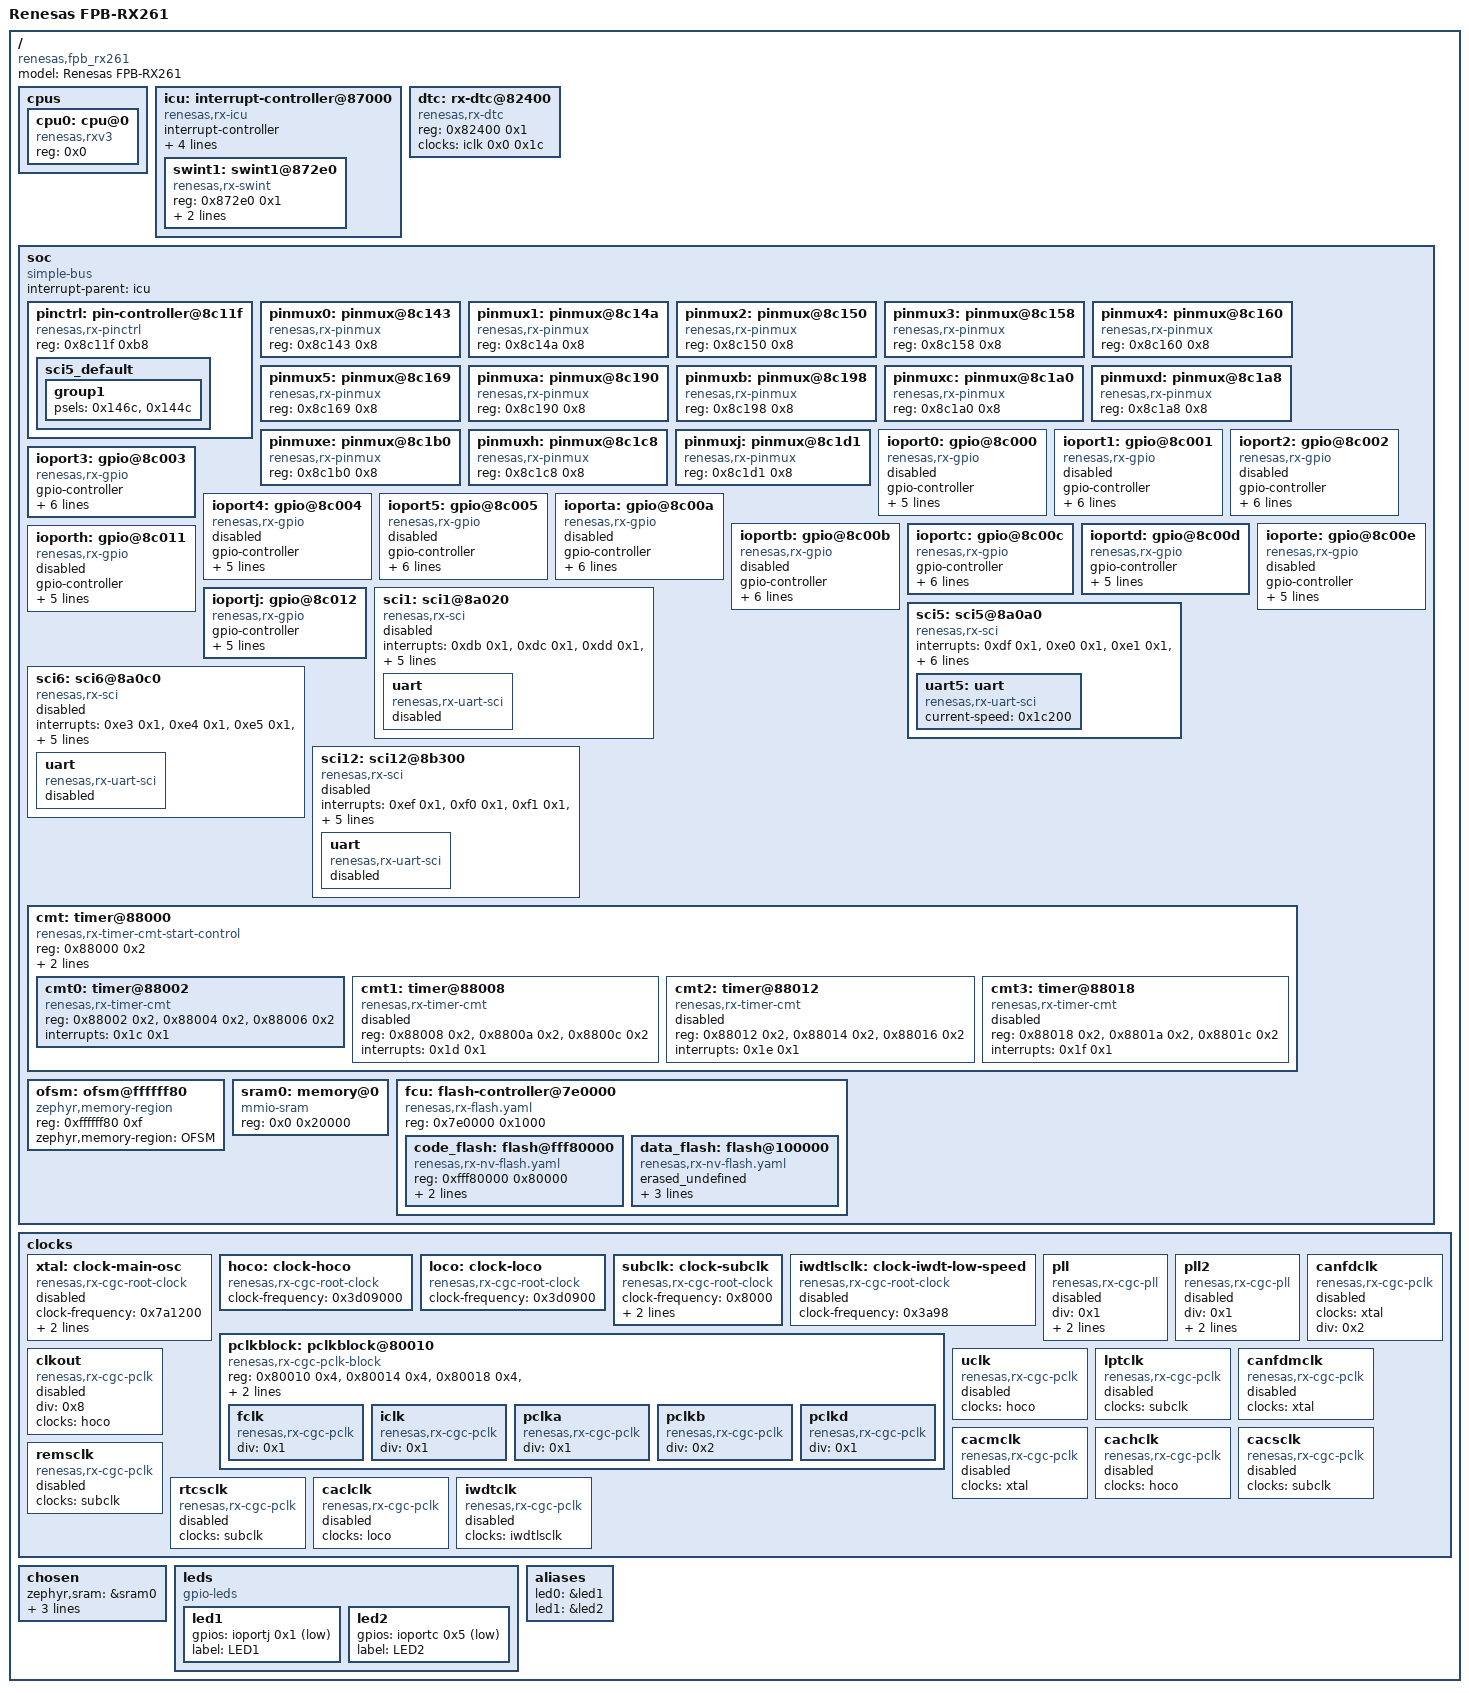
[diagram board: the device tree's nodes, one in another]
/dts-v1/;

/* node '/' defined in zephyr/dts/rx/renesas/rx261-common.dtsi:15 */
/ {
	#address-cells = < 0x1 >;         /* in zephyr/dts/rx/renesas/rx261-common.dtsi:16 */
	#size-cells = < 0x1 >;            /* in zephyr/dts/rx/renesas/rx261-common.dtsi:17 */
	model = "Renesas FPB-RX261";      /* in zephyr/boards/renesas/fpb_rx261/fpb_rx261.dts:14 */
	compatible = "renesas,fpb_rx261"; /* in zephyr/boards/renesas/fpb_rx261/fpb_rx261.dts:15 */

	/* node '/cpus' defined in zephyr/dts/rx/renesas/rx261-common.dtsi:19 */
	cpus {
		#address-cells = < 0x1 >; /* in zephyr/dts/rx/renesas/rx261-common.dtsi:20 */
		#size-cells = < 0x0 >;    /* in zephyr/dts/rx/renesas/rx261-common.dtsi:21 */

		/* node '/cpus/cpu@0' defined in zephyr/dts/rx/renesas/rx261-common.dtsi:23 */
		cpu0: cpu@0 {
			compatible = "renesas,rxv3"; /* in zephyr/dts/rx/renesas/rx261-common.dtsi:24 */
			device_type = "cpu";         /* in zephyr/dts/rx/renesas/rx261-common.dtsi:25 */
			reg = < 0x0 >;               /* in zephyr/dts/rx/renesas/rx261-common.dtsi:26 */
			status = "okay";             /* in zephyr/dts/rx/renesas/rx261-common.dtsi:27 */
		};
	};

	/* node '/interrupt-controller@87000' defined in zephyr/dts/rx/renesas/rx261-common.dtsi:31 */
	icu: interrupt-controller@87000 {
		#interrupt-cells = < 0x2 >;    /* in zephyr/dts/rx/renesas/rx261-common.dtsi:32 */
		#address-cells = < 0x1 >;      /* in zephyr/dts/rx/renesas/rx261-common.dtsi:33 */
		#size-cells = < 0x1 >;         /* in zephyr/dts/rx/renesas/rx261-common.dtsi:34 */
		compatible = "renesas,rx-icu"; /* in zephyr/dts/rx/renesas/rx261-common.dtsi:35 */
		interrupt-controller;          /* in zephyr/dts/rx/renesas/rx261-common.dtsi:36 */
		reg = < 0x87000 0xff >,
		      < 0x87200 0x1f >,
		      < 0x87300 0xff >,
		      < 0x872f0 0x2 >,
		      < 0x87500 0xf >,
		      < 0x87510 0x1 >,
		      < 0x87514 0x1 >,
		      < 0x87580 0x1 >,
		      < 0x87581 0x1 >,
		      < 0x87582 0x1 >;         /* in zephyr/dts/rx/renesas/rx261-common.dtsi:37 */
		reg-names = "IR",
		            "IER",
		            "IPR",
		            "FIR",
		            "IRQCR",
		            "IRQFLTE",
		            "IRQFLTC0",
		            "NMISR",
		            "NMIER",
		            "NMICLR";          /* in zephyr/dts/rx/renesas/rx261-common.dtsi:47 */
		phandle = < 0x1 >;             /* in zephyr/dts/rx/renesas/rx261-common.dtsi:54 */

		/* node '/interrupt-controller@87000/swint1@872e0' defined in zephyr/dts/rx/renesas/rx261-common.dtsi:50 */
		swint1: swint1@872e0 {
			compatible = "renesas,rx-swint"; /* in zephyr/dts/rx/renesas/rx261-common.dtsi:51 */
			reg = < 0x872e0 0x1 >;           /* in zephyr/dts/rx/renesas/rx261-common.dtsi:52 */
			interrupts = < 0x1b 0xe >;       /* in zephyr/dts/rx/renesas/rx261-common.dtsi:53 */
			interrupt-parent = < &icu >;     /* in zephyr/dts/rx/renesas/rx261-common.dtsi:54 */
			status = "okay";                 /* in zephyr/dts/rx/renesas/rx261-common.dtsi:55 */
		};
	};

	/* node '/rx-dtc@82400' defined in zephyr/dts/rx/renesas/rx261-common.dtsi:59 */
	dtc: rx-dtc@82400 {
		compatible = "renesas,rx-dtc"; /* in zephyr/dts/rx/renesas/rx261-common.dtsi:60 */
		reg = < 0x82400 0x1 >;         /* in zephyr/dts/rx/renesas/rx261-common.dtsi:61 */
		clocks = < &iclk 0x0 0x1c >;   /* in zephyr/dts/rx/renesas/rx261-common.dtsi:62 */
		status = "okay";               /* in zephyr/dts/rx/renesas/rx261-common.dtsi:63 */
		phandle = < 0x11 >;            /* in zephyr/dts/rx/renesas/rx261-common.dtsi:400 */
	};

	/* node '/soc' defined in zephyr/dts/rx/renesas/rx261-common.dtsi:66 */
	soc {
		#address-cells = < 0x1 >;    /* in zephyr/dts/rx/renesas/rx261-common.dtsi:67 */
		#size-cells = < 0x1 >;       /* in zephyr/dts/rx/renesas/rx261-common.dtsi:68 */
		device_type = "soc";         /* in zephyr/dts/rx/renesas/rx261-common.dtsi:69 */
		compatible = "simple-bus";   /* in zephyr/dts/rx/renesas/rx261-common.dtsi:70 */
		interrupt-parent = < &icu >; /* in zephyr/dts/rx/renesas/rx261-common.dtsi:71 */

		/* node '/soc/pin-controller@8c11f' defined in zephyr/dts/rx/renesas/rx261-common.dtsi:73 */
		pinctrl: pin-controller@8c11f {
			compatible = "renesas,rx-pinctrl"; /* in zephyr/dts/rx/renesas/rx261-common.dtsi:74 */
			reg = < 0x8c11f 0xb8 >;            /* in zephyr/dts/rx/renesas/rx261-common.dtsi:75 */
			status = "okay";                   /* in zephyr/dts/rx/renesas/rx261-common.dtsi:76 */

			/* node '/soc/pin-controller@8c11f/sci5_default' defined in zephyr/boards/renesas/fpb_rx261/fpb_rx261-pinctrl.dtsi:8 */
			sci5_default: sci5_default {
				phandle = < 0x12 >; /* in zephyr/boards/renesas/fpb_rx261/fpb_rx261.dts:78 */

				/* node '/soc/pin-controller@8c11f/sci5_default/group1' defined in zephyr/boards/renesas/fpb_rx261/fpb_rx261-pinctrl.dtsi:9 */
				group1 {
					psels = < 0x146c >,
					        < 0x144c >; /* in zephyr/boards/renesas/fpb_rx261/fpb_rx261-pinctrl.dtsi:10 */
				};
			};
		};

		/* node '/soc/pinmux@8c143' defined in zephyr/dts/rx/renesas/rx261-common.dtsi:79 */
		pinmux0: pinmux@8c143 {
			compatible = "renesas,rx-pinmux"; /* in zephyr/dts/rx/renesas/rx261-common.dtsi:80 */
			#pinmux-cells = < 0x2 >;          /* in zephyr/dts/rx/renesas/rx261-common.dtsi:81 */
			reg = < 0x8c143 0x8 >;            /* in zephyr/dts/rx/renesas/rx261-common.dtsi:82 */
			status = "okay";                  /* in zephyr/dts/rx/renesas/rx261-common.dtsi:83 */
			phandle = < 0x3 >;                /* in zephyr/dts/rx/renesas/rx261-common.dtsi:182 */
		};

		/* node '/soc/pinmux@8c14a' defined in zephyr/dts/rx/renesas/rx261-common.dtsi:86 */
		pinmux1: pinmux@8c14a {
			compatible = "renesas,rx-pinmux"; /* in zephyr/dts/rx/renesas/rx261-common.dtsi:87 */
			#pinmux-cells = < 0x2 >;          /* in zephyr/dts/rx/renesas/rx261-common.dtsi:88 */
			reg = < 0x8c14a 0x8 >;            /* in zephyr/dts/rx/renesas/rx261-common.dtsi:89 */
			status = "okay";                  /* in zephyr/dts/rx/renesas/rx261-common.dtsi:90 */
			phandle = < 0x4 >;                /* in zephyr/dts/rx/renesas/rx261-common.dtsi:200 */
		};

		/* node '/soc/pinmux@8c150' defined in zephyr/dts/rx/renesas/rx261-common.dtsi:93 */
		pinmux2: pinmux@8c150 {
			compatible = "renesas,rx-pinmux"; /* in zephyr/dts/rx/renesas/rx261-common.dtsi:94 */
			#pinmux-cells = < 0x2 >;          /* in zephyr/dts/rx/renesas/rx261-common.dtsi:95 */
			reg = < 0x8c150 0x8 >;            /* in zephyr/dts/rx/renesas/rx261-common.dtsi:96 */
			status = "okay";                  /* in zephyr/dts/rx/renesas/rx261-common.dtsi:97 */
			phandle = < 0x5 >;                /* in zephyr/dts/rx/renesas/rx261-common.dtsi:218 */
		};

		/* node '/soc/pinmux@8c158' defined in zephyr/dts/rx/renesas/rx261-common.dtsi:100 */
		pinmux3: pinmux@8c158 {
			compatible = "renesas,rx-pinmux"; /* in zephyr/dts/rx/renesas/rx261-common.dtsi:101 */
			#pinmux-cells = < 0x2 >;          /* in zephyr/dts/rx/renesas/rx261-common.dtsi:102 */
			reg = < 0x8c158 0x8 >;            /* in zephyr/dts/rx/renesas/rx261-common.dtsi:103 */
			status = "okay";                  /* in zephyr/dts/rx/renesas/rx261-common.dtsi:104 */
			phandle = < 0x6 >;                /* in zephyr/dts/rx/renesas/rx261-common.dtsi:236 */
		};

		/* node '/soc/pinmux@8c160' defined in zephyr/dts/rx/renesas/rx261-common.dtsi:107 */
		pinmux4: pinmux@8c160 {
			compatible = "renesas,rx-pinmux"; /* in zephyr/dts/rx/renesas/rx261-common.dtsi:108 */
			#pinmux-cells = < 0x2 >;          /* in zephyr/dts/rx/renesas/rx261-common.dtsi:109 */
			reg = < 0x8c160 0x8 >;            /* in zephyr/dts/rx/renesas/rx261-common.dtsi:110 */
			status = "okay";                  /* in zephyr/dts/rx/renesas/rx261-common.dtsi:111 */
			phandle = < 0x7 >;                /* in zephyr/dts/rx/renesas/rx261-common.dtsi:252 */
		};

		/* node '/soc/pinmux@8c169' defined in zephyr/dts/rx/renesas/rx261-common.dtsi:114 */
		pinmux5: pinmux@8c169 {
			compatible = "renesas,rx-pinmux"; /* in zephyr/dts/rx/renesas/rx261-common.dtsi:115 */
			#pinmux-cells = < 0x2 >;          /* in zephyr/dts/rx/renesas/rx261-common.dtsi:116 */
			reg = < 0x8c169 0x8 >;            /* in zephyr/dts/rx/renesas/rx261-common.dtsi:117 */
			status = "okay";                  /* in zephyr/dts/rx/renesas/rx261-common.dtsi:118 */
			phandle = < 0x8 >;                /* in zephyr/dts/rx/renesas/rx261-common.dtsi:270 */
		};

		/* node '/soc/pinmux@8c190' defined in zephyr/dts/rx/renesas/rx261-common.dtsi:121 */
		pinmuxa: pinmux@8c190 {
			compatible = "renesas,rx-pinmux"; /* in zephyr/dts/rx/renesas/rx261-common.dtsi:122 */
			#pinmux-cells = < 0x2 >;          /* in zephyr/dts/rx/renesas/rx261-common.dtsi:123 */
			reg = < 0x8c190 0x8 >;            /* in zephyr/dts/rx/renesas/rx261-common.dtsi:124 */
			status = "okay";                  /* in zephyr/dts/rx/renesas/rx261-common.dtsi:125 */
			phandle = < 0x9 >;                /* in zephyr/dts/rx/renesas/rx261-common.dtsi:288 */
		};

		/* node '/soc/pinmux@8c198' defined in zephyr/dts/rx/renesas/rx261-common.dtsi:128 */
		pinmuxb: pinmux@8c198 {
			compatible = "renesas,rx-pinmux"; /* in zephyr/dts/rx/renesas/rx261-common.dtsi:129 */
			#pinmux-cells = < 0x2 >;          /* in zephyr/dts/rx/renesas/rx261-common.dtsi:130 */
			reg = < 0x8c198 0x8 >;            /* in zephyr/dts/rx/renesas/rx261-common.dtsi:131 */
			status = "okay";                  /* in zephyr/dts/rx/renesas/rx261-common.dtsi:132 */
			phandle = < 0xa >;                /* in zephyr/dts/rx/renesas/rx261-common.dtsi:306 */
		};

		/* node '/soc/pinmux@8c1a0' defined in zephyr/dts/rx/renesas/rx261-common.dtsi:135 */
		pinmuxc: pinmux@8c1a0 {
			compatible = "renesas,rx-pinmux"; /* in zephyr/dts/rx/renesas/rx261-common.dtsi:136 */
			#pinmux-cells = < 0x2 >;          /* in zephyr/dts/rx/renesas/rx261-common.dtsi:137 */
			reg = < 0x8c1a0 0x8 >;            /* in zephyr/dts/rx/renesas/rx261-common.dtsi:138 */
			status = "okay";                  /* in zephyr/dts/rx/renesas/rx261-common.dtsi:139 */
			phandle = < 0xb >;                /* in zephyr/dts/rx/renesas/rx261-common.dtsi:324 */
		};

		/* node '/soc/pinmux@8c1a8' defined in zephyr/dts/rx/renesas/rx261-common.dtsi:142 */
		pinmuxd: pinmux@8c1a8 {
			compatible = "renesas,rx-pinmux"; /* in zephyr/dts/rx/renesas/rx261-common.dtsi:143 */
			#pinmux-cells = < 0x2 >;          /* in zephyr/dts/rx/renesas/rx261-common.dtsi:144 */
			reg = < 0x8c1a8 0x8 >;            /* in zephyr/dts/rx/renesas/rx261-common.dtsi:145 */
			status = "okay";                  /* in zephyr/dts/rx/renesas/rx261-common.dtsi:146 */
			phandle = < 0xc >;                /* in zephyr/dts/rx/renesas/rx261-common.dtsi:341 */
		};

		/* node '/soc/pinmux@8c1b0' defined in zephyr/dts/rx/renesas/rx261-common.dtsi:149 */
		pinmuxe: pinmux@8c1b0 {
			compatible = "renesas,rx-pinmux"; /* in zephyr/dts/rx/renesas/rx261-common.dtsi:150 */
			#pinmux-cells = < 0x2 >;          /* in zephyr/dts/rx/renesas/rx261-common.dtsi:151 */
			reg = < 0x8c1b0 0x8 >;            /* in zephyr/dts/rx/renesas/rx261-common.dtsi:152 */
			status = "okay";                  /* in zephyr/dts/rx/renesas/rx261-common.dtsi:153 */
			phandle = < 0xd >;                /* in zephyr/dts/rx/renesas/rx261-common.dtsi:358 */
		};

		/* node '/soc/pinmux@8c1c8' defined in zephyr/dts/rx/renesas/rx261-common.dtsi:156 */
		pinmuxh: pinmux@8c1c8 {
			compatible = "renesas,rx-pinmux"; /* in zephyr/dts/rx/renesas/rx261-common.dtsi:157 */
			#pinmux-cells = < 0x2 >;          /* in zephyr/dts/rx/renesas/rx261-common.dtsi:158 */
			reg = < 0x8c1c8 0x8 >;            /* in zephyr/dts/rx/renesas/rx261-common.dtsi:159 */
			status = "okay";                  /* in zephyr/dts/rx/renesas/rx261-common.dtsi:160 */
			phandle = < 0xe >;                /* in zephyr/dts/rx/renesas/rx261-common.dtsi:374 */
		};

		/* node '/soc/pinmux@8c1d1' defined in zephyr/dts/rx/renesas/rx261-common.dtsi:163 */
		pinmuxj: pinmux@8c1d1 {
			compatible = "renesas,rx-pinmux"; /* in zephyr/dts/rx/renesas/rx261-common.dtsi:164 */
			#pinmux-cells = < 0x2 >;          /* in zephyr/dts/rx/renesas/rx261-common.dtsi:165 */
			reg = < 0x8c1d1 0x8 >;            /* in zephyr/dts/rx/renesas/rx261-common.dtsi:166 */
			status = "okay";                  /* in zephyr/dts/rx/renesas/rx261-common.dtsi:167 */
			phandle = < 0xf >;                /* in zephyr/dts/rx/renesas/rx261-common.dtsi:390 */
		};

		/* node '/soc/gpio@8c000' defined in zephyr/dts/rx/renesas/rx261-common.dtsi:170 */
		ioport0: gpio@8c000 {
			compatible = "renesas,rx-gpio"; /* in zephyr/dts/rx/renesas/rx261-common.dtsi:171 */
			gpio-controller;                /* in zephyr/dts/rx/renesas/rx261-common.dtsi:172 */
			#gpio-cells = < 0x2 >;          /* in zephyr/dts/rx/renesas/rx261-common.dtsi:173 */
			ngpios = < 0x5 >;               /* in zephyr/dts/rx/renesas/rx261-common.dtsi:174 */
			port = < 0x0 >;                 /* in zephyr/dts/rx/renesas/rx261-common.dtsi:175 */
			reg = < 0x8c000 0x1 >,
			      < 0x8c020 0x1 >,
			      < 0x8c040 0x1 >,
			      < 0x8c060 0x1 >,
			      < 0x8c0c0 0x1 >;          /* in zephyr/dts/rx/renesas/rx261-common.dtsi:176 */
			reg-names = "PDR",
			            "PODR",
			            "PIDR",
			            "PMR",
			            "PCR";              /* in zephyr/dts/rx/renesas/rx261-common.dtsi:181 */
			pinmux = < &pinmux0 >;          /* in zephyr/dts/rx/renesas/rx261-common.dtsi:182 */
			status = "disabled";            /* in zephyr/dts/rx/renesas/rx261-common.dtsi:183 */
		};

		/* node '/soc/gpio@8c001' defined in zephyr/dts/rx/renesas/rx261-common.dtsi:186 */
		ioport1: gpio@8c001 {
			compatible = "renesas,rx-gpio"; /* in zephyr/dts/rx/renesas/rx261-common.dtsi:187 */
			gpio-controller;                /* in zephyr/dts/rx/renesas/rx261-common.dtsi:188 */
			#gpio-cells = < 0x2 >;          /* in zephyr/dts/rx/renesas/rx261-common.dtsi:189 */
			ngpios = < 0x8 >;               /* in zephyr/dts/rx/renesas/rx261-common.dtsi:190 */
			port = < 0x1 >;                 /* in zephyr/dts/rx/renesas/rx261-common.dtsi:191 */
			reg = < 0x8c001 0x1 >,
			      < 0x8c021 0x1 >,
			      < 0x8c041 0x1 >,
			      < 0x8c061 0x1 >,
			      < 0x8c082 0x1 >,
			      < 0x8c083 0x1 >,
			      < 0x8c0c1 0x1 >;          /* in zephyr/dts/rx/renesas/rx261-common.dtsi:192 */
			reg-names = "PDR",
			            "PODR",
			            "PIDR",
			            "PMR",
			            "ODR0",
			            "ODR1",
			            "PCR";              /* in zephyr/dts/rx/renesas/rx261-common.dtsi:199 */
			pinmux = < &pinmux1 >;          /* in zephyr/dts/rx/renesas/rx261-common.dtsi:200 */
			status = "disabled";            /* in zephyr/dts/rx/renesas/rx261-common.dtsi:201 */
		};

		/* node '/soc/gpio@8c002' defined in zephyr/dts/rx/renesas/rx261-common.dtsi:204 */
		ioport2: gpio@8c002 {
			compatible = "renesas,rx-gpio"; /* in zephyr/dts/rx/renesas/rx261-common.dtsi:205 */
			gpio-controller;                /* in zephyr/dts/rx/renesas/rx261-common.dtsi:206 */
			#gpio-cells = < 0x2 >;          /* in zephyr/dts/rx/renesas/rx261-common.dtsi:207 */
			ngpios = < 0x8 >;               /* in zephyr/dts/rx/renesas/rx261-common.dtsi:208 */
			port = < 0x2 >;                 /* in zephyr/dts/rx/renesas/rx261-common.dtsi:209 */
			reg = < 0x8c002 0x1 >,
			      < 0x8c022 0x1 >,
			      < 0x8c042 0x1 >,
			      < 0x8c062 0x1 >,
			      < 0x8c084 0x1 >,
			      < 0x8c085 0x1 >,
			      < 0x8c0c2 0x1 >;          /* in zephyr/dts/rx/renesas/rx261-common.dtsi:210 */
			reg-names = "PDR",
			            "PODR",
			            "PIDR",
			            "PMR",
			            "ODR0",
			            "ODR1",
			            "PCR";              /* in zephyr/dts/rx/renesas/rx261-common.dtsi:217 */
			pinmux = < &pinmux2 >;          /* in zephyr/dts/rx/renesas/rx261-common.dtsi:218 */
			status = "disabled";            /* in zephyr/dts/rx/renesas/rx261-common.dtsi:219 */
		};

		/* node '/soc/gpio@8c003' defined in zephyr/dts/rx/renesas/rx261-common.dtsi:222 */
		ioport3: gpio@8c003 {
			compatible = "renesas,rx-gpio"; /* in zephyr/dts/rx/renesas/rx261-common.dtsi:223 */
			gpio-controller;                /* in zephyr/dts/rx/renesas/rx261-common.dtsi:224 */
			#gpio-cells = < 0x2 >;          /* in zephyr/dts/rx/renesas/rx261-common.dtsi:225 */
			ngpios = < 0x8 >;               /* in zephyr/dts/rx/renesas/rx261-common.dtsi:226 */
			port = < 0x3 >;                 /* in zephyr/dts/rx/renesas/rx261-common.dtsi:227 */
			reg = < 0x8c003 0x1 >,
			      < 0x8c023 0x1 >,
			      < 0x8c043 0x1 >,
			      < 0x8c063 0x1 >,
			      < 0x8c086 0x1 >,
			      < 0x8c087 0x1 >,
			      < 0x8c0c3 0x1 >;          /* in zephyr/dts/rx/renesas/rx261-common.dtsi:228 */
			reg-names = "PDR",
			            "PODR",
			            "PIDR",
			            "PMR",
			            "ODR0",
			            "ODR1",
			            "PCR";              /* in zephyr/dts/rx/renesas/rx261-common.dtsi:235 */
			pinmux = < &pinmux3 >;          /* in zephyr/dts/rx/renesas/rx261-common.dtsi:236 */
			status = "okay";                /* in zephyr/boards/renesas/fpb_rx261/fpb_rx261.dts:66 */
		};

		/* node '/soc/gpio@8c004' defined in zephyr/dts/rx/renesas/rx261-common.dtsi:240 */
		ioport4: gpio@8c004 {
			compatible = "renesas,rx-gpio"; /* in zephyr/dts/rx/renesas/rx261-common.dtsi:241 */
			gpio-controller;                /* in zephyr/dts/rx/renesas/rx261-common.dtsi:242 */
			#gpio-cells = < 0x2 >;          /* in zephyr/dts/rx/renesas/rx261-common.dtsi:243 */
			ngpios = < 0x8 >;               /* in zephyr/dts/rx/renesas/rx261-common.dtsi:244 */
			port = < 0x4 >;                 /* in zephyr/dts/rx/renesas/rx261-common.dtsi:245 */
			reg = < 0x8c004 0x1 >,
			      < 0x8c024 0x1 >,
			      < 0x8c044 0x1 >,
			      < 0x8c064 0x1 >,
			      < 0x8c0c4 0x1 >;          /* in zephyr/dts/rx/renesas/rx261-common.dtsi:246 */
			reg-names = "PDR",
			            "PODR",
			            "PIDR",
			            "PMR",
			            "PCR";              /* in zephyr/dts/rx/renesas/rx261-common.dtsi:251 */
			pinmux = < &pinmux4 >;          /* in zephyr/dts/rx/renesas/rx261-common.dtsi:252 */
			status = "disabled";            /* in zephyr/dts/rx/renesas/rx261-common.dtsi:253 */
		};

		/* node '/soc/gpio@8c005' defined in zephyr/dts/rx/renesas/rx261-common.dtsi:256 */
		ioport5: gpio@8c005 {
			compatible = "renesas,rx-gpio"; /* in zephyr/dts/rx/renesas/rx261-common.dtsi:257 */
			gpio-controller;                /* in zephyr/dts/rx/renesas/rx261-common.dtsi:258 */
			#gpio-cells = < 0x2 >;          /* in zephyr/dts/rx/renesas/rx261-common.dtsi:259 */
			ngpios = < 0x8 >;               /* in zephyr/dts/rx/renesas/rx261-common.dtsi:260 */
			port = < 0x5 >;                 /* in zephyr/dts/rx/renesas/rx261-common.dtsi:261 */
			reg = < 0x8c005 0x1 >,
			      < 0x8c025 0x1 >,
			      < 0x8c045 0x1 >,
			      < 0x8c065 0x1 >,
			      < 0x8c08a 0x1 >,
			      < 0x8c08b 0x1 >,
			      < 0x8c0c5 0x1 >;          /* in zephyr/dts/rx/renesas/rx261-common.dtsi:262 */
			reg-names = "PDR",
			            "PODR",
			            "PIDR",
			            "PMR",
			            "ODR0",
			            "ODR1",
			            "PCR";              /* in zephyr/dts/rx/renesas/rx261-common.dtsi:269 */
			pinmux = < &pinmux5 >;          /* in zephyr/dts/rx/renesas/rx261-common.dtsi:270 */
			status = "disabled";            /* in zephyr/dts/rx/renesas/rx261-common.dtsi:271 */
		};

		/* node '/soc/gpio@8c00a' defined in zephyr/dts/rx/renesas/rx261-common.dtsi:274 */
		ioporta: gpio@8c00a {
			compatible = "renesas,rx-gpio"; /* in zephyr/dts/rx/renesas/rx261-common.dtsi:275 */
			gpio-controller;                /* in zephyr/dts/rx/renesas/rx261-common.dtsi:276 */
			#gpio-cells = < 0x2 >;          /* in zephyr/dts/rx/renesas/rx261-common.dtsi:277 */
			ngpios = < 0x8 >;               /* in zephyr/dts/rx/renesas/rx261-common.dtsi:278 */
			port = < 0xa >;                 /* in zephyr/dts/rx/renesas/rx261-common.dtsi:279 */
			reg = < 0x8c00a 0x1 >,
			      < 0x8c02a 0x1 >,
			      < 0x8c04a 0x1 >,
			      < 0x8c06a 0x1 >,
			      < 0x8c094 0x1 >,
			      < 0x8c095 0x1 >,
			      < 0x8c0ca 0x1 >;          /* in zephyr/dts/rx/renesas/rx261-common.dtsi:280 */
			reg-names = "PDR",
			            "PODR",
			            "PIDR",
			            "PMR",
			            "ODR0",
			            "ODR1",
			            "PCR";              /* in zephyr/dts/rx/renesas/rx261-common.dtsi:287 */
			pinmux = < &pinmuxa >;          /* in zephyr/dts/rx/renesas/rx261-common.dtsi:288 */
			status = "disabled";            /* in zephyr/dts/rx/renesas/rx261-common.dtsi:289 */
		};

		/* node '/soc/gpio@8c00b' defined in zephyr/dts/rx/renesas/rx261-common.dtsi:292 */
		ioportb: gpio@8c00b {
			compatible = "renesas,rx-gpio"; /* in zephyr/dts/rx/renesas/rx261-common.dtsi:293 */
			gpio-controller;                /* in zephyr/dts/rx/renesas/rx261-common.dtsi:294 */
			#gpio-cells = < 0x2 >;          /* in zephyr/dts/rx/renesas/rx261-common.dtsi:295 */
			ngpios = < 0x8 >;               /* in zephyr/dts/rx/renesas/rx261-common.dtsi:296 */
			port = < 0xb >;                 /* in zephyr/dts/rx/renesas/rx261-common.dtsi:297 */
			reg = < 0x8c00b 0x1 >,
			      < 0x8c02b 0x1 >,
			      < 0x8c04b 0x1 >,
			      < 0x8c06b 0x1 >,
			      < 0x8c096 0x1 >,
			      < 0x8c097 0x1 >,
			      < 0x8c0cb 0x1 >;          /* in zephyr/dts/rx/renesas/rx261-common.dtsi:298 */
			reg-names = "PDR",
			            "PODR",
			            "PIDR",
			            "PMR",
			            "ODR0",
			            "ODR1",
			            "PCR";              /* in zephyr/dts/rx/renesas/rx261-common.dtsi:305 */
			pinmux = < &pinmuxb >;          /* in zephyr/dts/rx/renesas/rx261-common.dtsi:306 */
			status = "disabled";            /* in zephyr/dts/rx/renesas/rx261-common.dtsi:307 */
		};

		/* node '/soc/gpio@8c00c' defined in zephyr/dts/rx/renesas/rx261-common.dtsi:310 */
		ioportc: gpio@8c00c {
			compatible = "renesas,rx-gpio"; /* in zephyr/dts/rx/renesas/rx261-common.dtsi:311 */
			gpio-controller;                /* in zephyr/dts/rx/renesas/rx261-common.dtsi:312 */
			#gpio-cells = < 0x2 >;          /* in zephyr/dts/rx/renesas/rx261-common.dtsi:313 */
			ngpios = < 0x8 >;               /* in zephyr/dts/rx/renesas/rx261-common.dtsi:314 */
			port = < 0xc >;                 /* in zephyr/dts/rx/renesas/rx261-common.dtsi:315 */
			reg = < 0x8c00c 0x1 >,
			      < 0x8c02c 0x1 >,
			      < 0x8c04c 0x1 >,
			      < 0x8c06c 0x1 >,
			      < 0x8c098 0x1 >,
			      < 0x8c099 0x1 >,
			      < 0x8c0cc 0x1 >;          /* in zephyr/dts/rx/renesas/rx261-common.dtsi:316 */
			reg-names = "PDR",
			            "PODR",
			            "PIDR",
			            "PMR",
			            "ODR0",
			            "ODR1",
			            "PCR";              /* in zephyr/dts/rx/renesas/rx261-common.dtsi:323 */
			pinmux = < &pinmuxc >;          /* in zephyr/dts/rx/renesas/rx261-common.dtsi:324 */
			status = "okay";                /* in zephyr/boards/renesas/fpb_rx261/fpb_rx261.dts:70 */
			phandle = < 0x19 >;             /* in zephyr/boards/renesas/fpb_rx261/fpb_rx261.dts:33 */
		};

		/* node '/soc/gpio@8c00d' defined in zephyr/dts/rx/renesas/rx261-common.dtsi:328 */
		ioportd: gpio@8c00d {
			compatible = "renesas,rx-gpio"; /* in zephyr/dts/rx/renesas/rx261-common.dtsi:329 */
			gpio-controller;                /* in zephyr/dts/rx/renesas/rx261-common.dtsi:330 */
			#gpio-cells = < 0x2 >;          /* in zephyr/dts/rx/renesas/rx261-common.dtsi:331 */
			ngpios = < 0x8 >;               /* in zephyr/dts/rx/renesas/rx261-common.dtsi:332 */
			port = < 0xd >;                 /* in zephyr/dts/rx/renesas/rx261-common.dtsi:333 */
			reg = < 0x8c00d 0x1 >,
			      < 0x8c02d 0x1 >,
			      < 0x8c04d 0x1 >,
			      < 0x8c06d 0x1 >,
			      < 0x8c09a 0x1 >,
			      < 0x8c0cd 0x1 >;          /* in zephyr/dts/rx/renesas/rx261-common.dtsi:334 */
			reg-names = "PDR",
			            "PODR",
			            "PIDR",
			            "PMR",
			            "ODR0",
			            "PCR";              /* in zephyr/dts/rx/renesas/rx261-common.dtsi:340 */
			pinmux = < &pinmuxd >;          /* in zephyr/dts/rx/renesas/rx261-common.dtsi:341 */
			status = "okay";                /* in zephyr/dts/rx/renesas/rx261-common.dtsi:342 */
		};

		/* node '/soc/gpio@8c00e' defined in zephyr/dts/rx/renesas/rx261-common.dtsi:345 */
		ioporte: gpio@8c00e {
			compatible = "renesas,rx-gpio"; /* in zephyr/dts/rx/renesas/rx261-common.dtsi:346 */
			gpio-controller;                /* in zephyr/dts/rx/renesas/rx261-common.dtsi:347 */
			#gpio-cells = < 0x2 >;          /* in zephyr/dts/rx/renesas/rx261-common.dtsi:348 */
			ngpios = < 0x8 >;               /* in zephyr/dts/rx/renesas/rx261-common.dtsi:349 */
			port = < 0xe >;                 /* in zephyr/dts/rx/renesas/rx261-common.dtsi:350 */
			reg = < 0x8c00e 0x1 >,
			      < 0x8c02e 0x1 >,
			      < 0x8c04e 0x1 >,
			      < 0x8c06e 0x1 >,
			      < 0x8c09c 0x1 >,
			      < 0x8c0ce 0x1 >;          /* in zephyr/dts/rx/renesas/rx261-common.dtsi:351 */
			reg-names = "PDR",
			            "PODR",
			            "PIDR",
			            "PMR",
			            "ODR0",
			            "PCR";              /* in zephyr/dts/rx/renesas/rx261-common.dtsi:357 */
			pinmux = < &pinmuxe >;          /* in zephyr/dts/rx/renesas/rx261-common.dtsi:358 */
			status = "disabled";            /* in zephyr/dts/rx/renesas/rx261-common.dtsi:359 */
		};

		/* node '/soc/gpio@8c011' defined in zephyr/dts/rx/renesas/rx261-common.dtsi:362 */
		ioporth: gpio@8c011 {
			compatible = "renesas,rx-gpio"; /* in zephyr/dts/rx/renesas/rx261-common.dtsi:363 */
			gpio-controller;                /* in zephyr/dts/rx/renesas/rx261-common.dtsi:364 */
			#gpio-cells = < 0x2 >;          /* in zephyr/dts/rx/renesas/rx261-common.dtsi:365 */
			ngpios = < 0x8 >;               /* in zephyr/dts/rx/renesas/rx261-common.dtsi:366 */
			port = < 0x11 >;                /* in zephyr/dts/rx/renesas/rx261-common.dtsi:367 */
			reg = < 0x8c011 0x1 >,
			      < 0x8c031 0x1 >,
			      < 0x8c051 0x1 >,
			      < 0x8c071 0x1 >,
			      < 0x8c0d1 0x1 >;          /* in zephyr/dts/rx/renesas/rx261-common.dtsi:368 */
			reg-names = "PDR",
			            "PODR",
			            "PIDR",
			            "PMR",
			            "PCR";              /* in zephyr/dts/rx/renesas/rx261-common.dtsi:373 */
			pinmux = < &pinmuxh >;          /* in zephyr/dts/rx/renesas/rx261-common.dtsi:374 */
			status = "disabled";            /* in zephyr/dts/rx/renesas/rx261-common.dtsi:375 */
		};

		/* node '/soc/gpio@8c012' defined in zephyr/dts/rx/renesas/rx261-common.dtsi:378 */
		ioportj: gpio@8c012 {
			compatible = "renesas,rx-gpio"; /* in zephyr/dts/rx/renesas/rx261-common.dtsi:379 */
			gpio-controller;                /* in zephyr/dts/rx/renesas/rx261-common.dtsi:380 */
			#gpio-cells = < 0x2 >;          /* in zephyr/dts/rx/renesas/rx261-common.dtsi:381 */
			ngpios = < 0x8 >;               /* in zephyr/dts/rx/renesas/rx261-common.dtsi:382 */
			port = < 0x12 >;                /* in zephyr/dts/rx/renesas/rx261-common.dtsi:383 */
			reg = < 0x8c012 0x1 >,
			      < 0x8c032 0x1 >,
			      < 0x8c052 0x1 >,
			      < 0x8c072 0x1 >,
			      < 0x8c0d2 0x1 >;          /* in zephyr/dts/rx/renesas/rx261-common.dtsi:384 */
			reg-names = "PDR",
			            "PODR",
			            "PIDR",
			            "PMR",
			            "PCR";              /* in zephyr/dts/rx/renesas/rx261-common.dtsi:389 */
			pinmux = < &pinmuxj >;          /* in zephyr/dts/rx/renesas/rx261-common.dtsi:390 */
			status = "okay";                /* in zephyr/boards/renesas/fpb_rx261/fpb_rx261.dts:74 */
			phandle = < 0x18 >;             /* in zephyr/boards/renesas/fpb_rx261/fpb_rx261.dts:28 */
		};

		/* node '/soc/sci1@8a020' defined in zephyr/dts/rx/renesas/rx261-common.dtsi:394 */
		sci1: sci1@8a020 {
			compatible = "renesas,rx-sci"; /* in zephyr/dts/rx/renesas/rx261-common.dtsi:395 */
			interrupts = < 0xdb 0x1 >,
			             < 0xdc 0x1 >,
			             < 0xdd 0x1 >,
			             < 0xda 0x1 >;     /* in zephyr/dts/rx/renesas/rx261-common.dtsi:396 */
			interrupt-names = "rxi",
			                  "txi",
			                  "tei",
			                  "eri";       /* in zephyr/dts/rx/renesas/rx261-common.dtsi:397 */
			reg = < 0x8a020 0x20 >;        /* in zephyr/dts/rx/renesas/rx261-common.dtsi:398 */
			clocks = < &pclkb 0x1 0x1e >;  /* in zephyr/dts/rx/renesas/rx261-common.dtsi:399 */
			dtc = < &dtc >;                /* in zephyr/dts/rx/renesas/rx261-common.dtsi:400 */
			channel = < 0x1 >;             /* in zephyr/dts/rx/renesas/rx261-common.dtsi:401 */
			status = "disabled";           /* in zephyr/dts/rx/renesas/rx261-common.dtsi:402 */

			/* node '/soc/sci1@8a020/uart' defined in zephyr/dts/rx/renesas/rx261-common.dtsi:404 */
			uart {
				compatible = "renesas,rx-uart-sci"; /* in zephyr/dts/rx/renesas/rx261-common.dtsi:405 */
				status = "disabled";                /* in zephyr/dts/rx/renesas/rx261-common.dtsi:406 */
			};
		};

		/* node '/soc/sci5@8a0a0' defined in zephyr/dts/rx/renesas/rx261-common.dtsi:410 */
		sci5: sci5@8a0a0 {
			compatible = "renesas,rx-sci"; /* in zephyr/dts/rx/renesas/rx261-common.dtsi:411 */
			interrupts = < 0xdf 0x1 >,
			             < 0xe0 0x1 >,
			             < 0xe1 0x1 >,
			             < 0xde 0x1 >;     /* in zephyr/dts/rx/renesas/rx261-common.dtsi:412 */
			interrupt-names = "rxi",
			                  "txi",
			                  "tei",
			                  "eri";       /* in zephyr/dts/rx/renesas/rx261-common.dtsi:413 */
			reg = < 0x8a0a0 0x20 >;        /* in zephyr/dts/rx/renesas/rx261-common.dtsi:414 */
			clocks = < &pclkb 0x1 0x1a >;  /* in zephyr/dts/rx/renesas/rx261-common.dtsi:415 */
			dtc = < &dtc >;                /* in zephyr/dts/rx/renesas/rx261-common.dtsi:416 */
			channel = < 0x5 >;             /* in zephyr/dts/rx/renesas/rx261-common.dtsi:417 */
			pinctrl-0 = < &sci5_default >; /* in zephyr/boards/renesas/fpb_rx261/fpb_rx261.dts:78 */
			pinctrl-names = "default";     /* in zephyr/boards/renesas/fpb_rx261/fpb_rx261.dts:79 */
			status = "okay";               /* in zephyr/boards/renesas/fpb_rx261/fpb_rx261.dts:80 */

			/* node '/soc/sci5@8a0a0/uart' defined in zephyr/dts/rx/renesas/rx261-common.dtsi:420 */
			uart5: uart {
				compatible = "renesas,rx-uart-sci"; /* in zephyr/dts/rx/renesas/rx261-common.dtsi:421 */
				current-speed = < 0x1c200 >;        /* in zephyr/boards/renesas/fpb_rx261/fpb_rx261.dts:83 */
				status = "okay";                    /* in zephyr/boards/renesas/fpb_rx261/fpb_rx261.dts:84 */
			};
		};

		/* node '/soc/sci6@8a0c0' defined in zephyr/dts/rx/renesas/rx261-common.dtsi:426 */
		sci6: sci6@8a0c0 {
			compatible = "renesas,rx-sci"; /* in zephyr/dts/rx/renesas/rx261-common.dtsi:427 */
			interrupts = < 0xe3 0x1 >,
			             < 0xe4 0x1 >,
			             < 0xe5 0x1 >,
			             < 0xe2 0x1 >;     /* in zephyr/dts/rx/renesas/rx261-common.dtsi:428 */
			interrupt-names = "rxi",
			                  "txi",
			                  "tei",
			                  "eri";       /* in zephyr/dts/rx/renesas/rx261-common.dtsi:429 */
			reg = < 0x8a0c0 0x20 >;        /* in zephyr/dts/rx/renesas/rx261-common.dtsi:430 */
			clocks = < &pclkb 0x1 0x19 >;  /* in zephyr/dts/rx/renesas/rx261-common.dtsi:431 */
			dtc = < &dtc >;                /* in zephyr/dts/rx/renesas/rx261-common.dtsi:432 */
			channel = < 0x6 >;             /* in zephyr/dts/rx/renesas/rx261-common.dtsi:433 */
			status = "disabled";           /* in zephyr/dts/rx/renesas/rx261-common.dtsi:434 */

			/* node '/soc/sci6@8a0c0/uart' defined in zephyr/dts/rx/renesas/rx261-common.dtsi:436 */
			uart {
				compatible = "renesas,rx-uart-sci"; /* in zephyr/dts/rx/renesas/rx261-common.dtsi:437 */
				status = "disabled";                /* in zephyr/dts/rx/renesas/rx261-common.dtsi:438 */
			};
		};

		/* node '/soc/sci12@8b300' defined in zephyr/dts/rx/renesas/rx261-common.dtsi:442 */
		sci12: sci12@8b300 {
			compatible = "renesas,rx-sci"; /* in zephyr/dts/rx/renesas/rx261-common.dtsi:443 */
			interrupts = < 0xef 0x1 >,
			             < 0xf0 0x1 >,
			             < 0xf1 0x1 >,
			             < 0xee 0x1 >;     /* in zephyr/dts/rx/renesas/rx261-common.dtsi:444 */
			interrupt-names = "rxi",
			                  "txi",
			                  "tei",
			                  "eri";       /* in zephyr/dts/rx/renesas/rx261-common.dtsi:445 */
			reg = < 0x8b300 0x20 >;        /* in zephyr/dts/rx/renesas/rx261-common.dtsi:446 */
			clocks = < &pclkb 0x1 0x4 >;   /* in zephyr/dts/rx/renesas/rx261-common.dtsi:447 */
			dtc = < &dtc >;                /* in zephyr/dts/rx/renesas/rx261-common.dtsi:448 */
			channel = < 0xc >;             /* in zephyr/dts/rx/renesas/rx261-common.dtsi:449 */
			status = "disabled";           /* in zephyr/dts/rx/renesas/rx261-common.dtsi:450 */

			/* node '/soc/sci12@8b300/uart' defined in zephyr/dts/rx/renesas/rx261-common.dtsi:452 */
			uart {
				compatible = "renesas,rx-uart-sci"; /* in zephyr/dts/rx/renesas/rx261-common.dtsi:453 */
				status = "disabled";                /* in zephyr/dts/rx/renesas/rx261-common.dtsi:454 */
			};
		};

		/* node '/soc/timer@88000' defined in zephyr/dts/rx/renesas/rx261-common.dtsi:458 */
		cmt: timer@88000 {
			compatible = "renesas,rx-timer-cmt-start-control"; /* in zephyr/dts/rx/renesas/rx261-common.dtsi:459 */
			#address-cells = < 0x1 >;                          /* in zephyr/dts/rx/renesas/rx261-common.dtsi:460 */
			#size-cells = < 0x1 >;                             /* in zephyr/dts/rx/renesas/rx261-common.dtsi:461 */
			reg = < 0x88000 0x2 >;                             /* in zephyr/dts/rx/renesas/rx261-common.dtsi:462 */
			clocks = < &pclkb 0x0 0xf >;                       /* in zephyr/dts/rx/renesas/rx261-common.dtsi:463 */
			reg-names = "CMSTR0";                              /* in zephyr/dts/rx/renesas/rx261-common.dtsi:464 */
			clock-frequency = < 0x3d0900 >;                    /* in zephyr/boards/renesas/fpb_rx261/fpb_rx261.dts:49 */
			status = "okay";                                   /* in zephyr/boards/renesas/fpb_rx261/fpb_rx261.dts:50 */

			/* node '/soc/timer@88000/timer@88002' defined in zephyr/dts/rx/renesas/rx261-common.dtsi:467 */
			cmt0: timer@88002 {
				compatible = "renesas,rx-timer-cmt"; /* in zephyr/dts/rx/renesas/rx261-common.dtsi:468 */
				#address-cells = < 0x1 >;            /* in zephyr/dts/rx/renesas/rx261-common.dtsi:469 */
				#size-cells = < 0x1 >;               /* in zephyr/dts/rx/renesas/rx261-common.dtsi:470 */
				reg = < 0x88002 0x2 >,
				      < 0x88004 0x2 >,
				      < 0x88006 0x2 >;               /* in zephyr/dts/rx/renesas/rx261-common.dtsi:471 */
				reg-names = "CMCR",
				            "CMCNT",
				            "CMCOR";                 /* in zephyr/dts/rx/renesas/rx261-common.dtsi:474 */
				interrupts = < 0x1c 0x1 >;           /* in zephyr/dts/rx/renesas/rx261-common.dtsi:475 */
				interrupt-names = "cmi";             /* in zephyr/dts/rx/renesas/rx261-common.dtsi:476 */
				status = "okay";                     /* in zephyr/dts/rx/renesas/rx261-common.dtsi:477 */
			};

			/* node '/soc/timer@88000/timer@88008' defined in zephyr/dts/rx/renesas/rx261-common.dtsi:480 */
			cmt1: timer@88008 {
				compatible = "renesas,rx-timer-cmt"; /* in zephyr/dts/rx/renesas/rx261-common.dtsi:481 */
				reg = < 0x88008 0x2 >,
				      < 0x8800a 0x2 >,
				      < 0x8800c 0x2 >;               /* in zephyr/dts/rx/renesas/rx261-common.dtsi:482 */
				reg-names = "CMCR",
				            "CMCNT",
				            "CMCOR";                 /* in zephyr/dts/rx/renesas/rx261-common.dtsi:485 */
				interrupts = < 0x1d 0x1 >;           /* in zephyr/dts/rx/renesas/rx261-common.dtsi:486 */
				interrupt-names = "cmi";             /* in zephyr/dts/rx/renesas/rx261-common.dtsi:487 */
				status = "disabled";                 /* in zephyr/dts/rx/renesas/rx261-common.dtsi:488 */
			};

			/* node '/soc/timer@88000/timer@88012' defined in zephyr/dts/rx/renesas/rx261-common.dtsi:491 */
			cmt2: timer@88012 {
				compatible = "renesas,rx-timer-cmt"; /* in zephyr/dts/rx/renesas/rx261-common.dtsi:492 */
				reg = < 0x88012 0x2 >,
				      < 0x88014 0x2 >,
				      < 0x88016 0x2 >;               /* in zephyr/dts/rx/renesas/rx261-common.dtsi:493 */
				reg-names = "CMCR",
				            "CMCNT",
				            "CMCOR";                 /* in zephyr/dts/rx/renesas/rx261-common.dtsi:496 */
				interrupts = < 0x1e 0x1 >;           /* in zephyr/dts/rx/renesas/rx261-common.dtsi:497 */
				interrupt-names = "cmi";             /* in zephyr/dts/rx/renesas/rx261-common.dtsi:498 */
				status = "disabled";                 /* in zephyr/dts/rx/renesas/rx261-common.dtsi:499 */
			};

			/* node '/soc/timer@88000/timer@88018' defined in zephyr/dts/rx/renesas/rx261-common.dtsi:502 */
			cmt3: timer@88018 {
				compatible = "renesas,rx-timer-cmt"; /* in zephyr/dts/rx/renesas/rx261-common.dtsi:503 */
				reg = < 0x88018 0x2 >,
				      < 0x8801a 0x2 >,
				      < 0x8801c 0x2 >;               /* in zephyr/dts/rx/renesas/rx261-common.dtsi:504 */
				reg-names = "CMCR",
				            "CMCNT",
				            "CMCOR";                 /* in zephyr/dts/rx/renesas/rx261-common.dtsi:507 */
				interrupts = < 0x1f 0x1 >;           /* in zephyr/dts/rx/renesas/rx261-common.dtsi:508 */
				interrupt-names = "cmi";             /* in zephyr/dts/rx/renesas/rx261-common.dtsi:509 */
				status = "disabled";                 /* in zephyr/dts/rx/renesas/rx261-common.dtsi:510 */
			};
		};

		/* node '/soc/ofsm@ffffff80' defined in zephyr/dts/rx/renesas/rx261-common.dtsi:514 */
		ofsm: ofsm@ffffff80 {
			compatible = "zephyr,memory-region"; /* in zephyr/dts/rx/renesas/rx261-common.dtsi:515 */
			reg = < 0xffffff80 0xf >;            /* in zephyr/dts/rx/renesas/rx261-common.dtsi:516 */
			zephyr,memory-region = "OFSM";       /* in zephyr/dts/rx/renesas/rx261-common.dtsi:517 */
			status = "okay";                     /* in zephyr/dts/rx/renesas/rx261-common.dtsi:518 */
		};

		/* node '/soc/memory@0' defined in zephyr/dts/rx/renesas/r5f52618bgfp.dtsi:208 */
		sram0: memory@0 {
			device_type = "memory";   /* in zephyr/dts/rx/renesas/r5f52618bgfp.dtsi:209 */
			compatible = "mmio-sram"; /* in zephyr/dts/rx/renesas/r5f52618bgfp.dtsi:210 */
			reg = < 0x0 0x20000 >;    /* in zephyr/dts/rx/renesas/r5f52618bgfp.dtsi:211 */
		};

		/* node '/soc/flash-controller@7e0000' defined in zephyr/dts/rx/renesas/r5f52618bgfp.dtsi:214 */
		fcu: flash-controller@7e0000 {
			#address-cells = < 0x1 >;             /* in zephyr/dts/rx/renesas/r5f52618bgfp.dtsi:215 */
			#size-cells = < 0x1 >;                /* in zephyr/dts/rx/renesas/r5f52618bgfp.dtsi:216 */
			compatible = "renesas,rx-flash.yaml"; /* in zephyr/dts/rx/renesas/r5f52618bgfp.dtsi:217 */
			reg = < 0x7e0000 0x1000 >;            /* in zephyr/dts/rx/renesas/r5f52618bgfp.dtsi:218 */

			/* node '/soc/flash-controller@7e0000/flash@fff80000' defined in zephyr/dts/rx/renesas/r5f52618bgfp.dtsi:220 */
			code_flash: flash@fff80000 {
				compatible = "renesas,rx-nv-flash.yaml"; /* in zephyr/dts/rx/renesas/r5f52618bgfp.dtsi:221 */
				reg = < 0xfff80000 0x80000 >;            /* in zephyr/dts/rx/renesas/r5f52618bgfp.dtsi:222 */
				write-block-size = < 0x4 >;              /* in zephyr/dts/rx/renesas/r5f52618bgfp.dtsi:223 */
				erase-block-size = < 0x400 >;            /* in zephyr/dts/rx/renesas/r5f52618bgfp.dtsi:224 */
			};

			/* node '/soc/flash-controller@7e0000/flash@100000' defined in zephyr/dts/rx/renesas/r5f52618bgfp.dtsi:227 */
			data_flash: flash@100000 {
				compatible = "renesas,rx-nv-flash.yaml"; /* in zephyr/dts/rx/renesas/r5f52618bgfp.dtsi:228 */
				erased_undefined;                        /* in zephyr/dts/rx/renesas/r5f52618bgfp.dtsi:229 */
				reg = < 0x100000 0x2000 >;               /* in zephyr/dts/rx/renesas/r5f52618bgfp.dtsi:230 */
				write_block_size = < 0x1 >;              /* in zephyr/dts/rx/renesas/r5f52618bgfp.dtsi:231 */
				erase-block-size = < 0x400 >;            /* in zephyr/dts/rx/renesas/r5f52618bgfp.dtsi:232 */
			};
		};
	};

	/* node '/clocks' defined in zephyr/dts/rx/renesas/r5f52618bgfp.dtsi:12 */
	clocks: clocks {
		#address-cells = < 0x1 >; /* in zephyr/dts/rx/renesas/r5f52618bgfp.dtsi:13 */
		#size-cells = < 0x1 >;    /* in zephyr/dts/rx/renesas/r5f52618bgfp.dtsi:14 */

		/* node '/clocks/clock-main-osc' defined in zephyr/dts/rx/renesas/r5f52618bgfp.dtsi:16 */
		xtal: clock-main-osc {
			compatible = "renesas,rx-cgc-root-clock"; /* in zephyr/dts/rx/renesas/r5f52618bgfp.dtsi:17 */
			clock-frequency = < 0x7a1200 >;           /* in zephyr/dts/rx/renesas/r5f52618bgfp.dtsi:18 */
			mosel = < 0x0 >;                          /* in zephyr/dts/rx/renesas/r5f52618bgfp.dtsi:19 */
			stabilization-time = < 0x4 >;             /* in zephyr/dts/rx/renesas/r5f52618bgfp.dtsi:20 */
			#clock-cells = < 0x0 >;                   /* in zephyr/dts/rx/renesas/r5f52618bgfp.dtsi:21 */
			status = "disabled";                      /* in zephyr/dts/rx/renesas/r5f52618bgfp.dtsi:22 */
			phandle = < 0x13 >;                       /* in zephyr/dts/rx/renesas/r5f52618bgfp.dtsi:59 */
		};

		/* node '/clocks/clock-hoco' defined in zephyr/dts/rx/renesas/r5f52618bgfp.dtsi:25 */
		hoco: clock-hoco {
			compatible = "renesas,rx-cgc-root-clock"; /* in zephyr/dts/rx/renesas/r5f52618bgfp.dtsi:26 */
			clock-frequency = < 0x3d09000 >;          /* in zephyr/dts/rx/renesas/r5f52618bgfp.dtsi:27 */
			#clock-cells = < 0x0 >;                   /* in zephyr/dts/rx/renesas/r5f52618bgfp.dtsi:28 */
			status = "okay";                          /* in zephyr/dts/rx/renesas/r5f52618bgfp.dtsi:29 */
			phandle = < 0x14 >;                       /* in zephyr/boards/renesas/fpb_rx261/fpb_rx261.dts:54 */
		};

		/* node '/clocks/clock-loco' defined in zephyr/dts/rx/renesas/r5f52618bgfp.dtsi:32 */
		loco: clock-loco {
			compatible = "renesas,rx-cgc-root-clock"; /* in zephyr/dts/rx/renesas/r5f52618bgfp.dtsi:33 */
			clock-frequency = < 0x3d0900 >;           /* in zephyr/dts/rx/renesas/r5f52618bgfp.dtsi:34 */
			#clock-cells = < 0x0 >;                   /* in zephyr/dts/rx/renesas/r5f52618bgfp.dtsi:35 */
			status = "okay";                          /* in zephyr/dts/rx/renesas/r5f52618bgfp.dtsi:36 */
			phandle = < 0x16 >;                       /* in zephyr/dts/rx/renesas/r5f52618bgfp.dtsi:194 */
		};

		/* node '/clocks/clock-subclk' defined in zephyr/dts/rx/renesas/r5f52618bgfp.dtsi:39 */
		subclk: clock-subclk {
			compatible = "renesas,rx-cgc-root-clock"; /* in zephyr/dts/rx/renesas/r5f52618bgfp.dtsi:40 */
			clock-frequency = < 0x8000 >;             /* in zephyr/dts/rx/renesas/r5f52618bgfp.dtsi:41 */
			drive-capacity = < 0x0 >;                 /* in zephyr/dts/rx/renesas/r5f52618bgfp.dtsi:42 */
			mosel = < 0x0 >;                          /* in zephyr/dts/rx/renesas/r5f52618bgfp.dtsi:43 */
			#clock-cells = < 0x0 >;                   /* in zephyr/dts/rx/renesas/r5f52618bgfp.dtsi:44 */
			status = "okay";                          /* in zephyr/boards/renesas/fpb_rx261/fpb_rx261.dts:45 */
			phandle = < 0x15 >;                       /* in zephyr/dts/rx/renesas/r5f52618bgfp.dtsi:145 */
		};

		/* node '/clocks/clock-iwdt-low-speed' defined in zephyr/dts/rx/renesas/r5f52618bgfp.dtsi:48 */
		iwdtlsclk: clock-iwdt-low-speed {
			compatible = "renesas,rx-cgc-root-clock"; /* in zephyr/dts/rx/renesas/r5f52618bgfp.dtsi:49 */
			clock-frequency = < 0x3a98 >;             /* in zephyr/dts/rx/renesas/r5f52618bgfp.dtsi:50 */
			#clock-cells = < 0x0 >;                   /* in zephyr/dts/rx/renesas/r5f52618bgfp.dtsi:51 */
			status = "disabled";                      /* in zephyr/dts/rx/renesas/r5f52618bgfp.dtsi:52 */
			phandle = < 0x17 >;                       /* in zephyr/dts/rx/renesas/r5f52618bgfp.dtsi:201 */
		};

		/* node '/clocks/pll' defined in zephyr/dts/rx/renesas/r5f52618bgfp.dtsi:55 */
		pll: pll {
			compatible = "renesas,rx-cgc-pll"; /* in zephyr/dts/rx/renesas/r5f52618bgfp.dtsi:56 */
			#clock-cells = < 0x0 >;            /* in zephyr/dts/rx/renesas/r5f52618bgfp.dtsi:57 */
			div = < 0x1 >;                     /* in zephyr/dts/rx/renesas/r5f52618bgfp.dtsi:58 */
			clocks = < &xtal >;                /* in zephyr/dts/rx/renesas/r5f52618bgfp.dtsi:59 */
			mul = < 0xf >;                     /* in zephyr/dts/rx/renesas/r5f52618bgfp.dtsi:60 */
			status = "disabled";               /* in zephyr/dts/rx/renesas/r5f52618bgfp.dtsi:61 */
		};

		/* node '/clocks/pll2' defined in zephyr/dts/rx/renesas/r5f52618bgfp.dtsi:64 */
		pll2: pll2 {
			compatible = "renesas,rx-cgc-pll"; /* in zephyr/dts/rx/renesas/r5f52618bgfp.dtsi:65 */
			#clock-cells = < 0x0 >;            /* in zephyr/dts/rx/renesas/r5f52618bgfp.dtsi:66 */
			div = < 0x1 >;                     /* in zephyr/dts/rx/renesas/r5f52618bgfp.dtsi:67 */
			clocks = < &xtal >;                /* in zephyr/dts/rx/renesas/r5f52618bgfp.dtsi:68 */
			mul = < 0xb >;                     /* in zephyr/dts/rx/renesas/r5f52618bgfp.dtsi:69 */
			status = "disabled";               /* in zephyr/dts/rx/renesas/r5f52618bgfp.dtsi:70 */
		};

		/* node '/clocks/pclkblock@80010' defined in zephyr/dts/rx/renesas/r5f52618bgfp.dtsi:73 */
		pclkblock: pclkblock@80010 {
			compatible = "renesas,rx-cgc-pclk-block"; /* in zephyr/dts/rx/renesas/r5f52618bgfp.dtsi:74 */
			reg = < 0x80010 0x4 >,
			      < 0x80014 0x4 >,
			      < 0x80018 0x4 >,
			      < 0x8001c 0x4 >;                    /* in zephyr/dts/rx/renesas/r5f52618bgfp.dtsi:75 */
			reg-names = "MSTPA",
			            "MSTPB",
			            "MSTPC",
			            "MSTPD";                      /* in zephyr/dts/rx/renesas/r5f52618bgfp.dtsi:79 */
			#clock-cells = < 0x0 >;                   /* in zephyr/dts/rx/renesas/r5f52618bgfp.dtsi:80 */
			status = "okay";                          /* in zephyr/dts/rx/renesas/r5f52618bgfp.dtsi:82 */
			clocks = < &hoco >;                       /* in zephyr/boards/renesas/fpb_rx261/fpb_rx261.dts:54 */

			/* node '/clocks/pclkblock@80010/fclk' defined in zephyr/dts/rx/renesas/r5f52618bgfp.dtsi:84 */
			fclk: fclk {
				compatible = "renesas,rx-cgc-pclk"; /* in zephyr/dts/rx/renesas/r5f52618bgfp.dtsi:85 */
				div = < 0x1 >;                      /* in zephyr/dts/rx/renesas/r5f52618bgfp.dtsi:86 */
				#clock-cells = < 0x2 >;             /* in zephyr/dts/rx/renesas/r5f52618bgfp.dtsi:87 */
				status = "okay";                    /* in zephyr/dts/rx/renesas/r5f52618bgfp.dtsi:88 */
			};

			/* node '/clocks/pclkblock@80010/iclk' defined in zephyr/dts/rx/renesas/r5f52618bgfp.dtsi:91 */
			iclk: iclk {
				compatible = "renesas,rx-cgc-pclk"; /* in zephyr/dts/rx/renesas/r5f52618bgfp.dtsi:92 */
				div = < 0x1 >;                      /* in zephyr/dts/rx/renesas/r5f52618bgfp.dtsi:93 */
				#clock-cells = < 0x2 >;             /* in zephyr/dts/rx/renesas/r5f52618bgfp.dtsi:94 */
				status = "okay";                    /* in zephyr/dts/rx/renesas/r5f52618bgfp.dtsi:95 */
				phandle = < 0x2 >;                  /* in zephyr/dts/rx/renesas/rx261-common.dtsi:62 */
			};

			/* node '/clocks/pclkblock@80010/pclka' defined in zephyr/dts/rx/renesas/r5f52618bgfp.dtsi:98 */
			pclka: pclka {
				compatible = "renesas,rx-cgc-pclk"; /* in zephyr/dts/rx/renesas/r5f52618bgfp.dtsi:99 */
				div = < 0x1 >;                      /* in zephyr/dts/rx/renesas/r5f52618bgfp.dtsi:100 */
				#clock-cells = < 0x2 >;             /* in zephyr/dts/rx/renesas/r5f52618bgfp.dtsi:101 */
				status = "okay";                    /* in zephyr/dts/rx/renesas/r5f52618bgfp.dtsi:102 */
			};

			/* node '/clocks/pclkblock@80010/pclkb' defined in zephyr/dts/rx/renesas/r5f52618bgfp.dtsi:105 */
			pclkb: pclkb {
				compatible = "renesas,rx-cgc-pclk"; /* in zephyr/dts/rx/renesas/r5f52618bgfp.dtsi:106 */
				div = < 0x2 >;                      /* in zephyr/dts/rx/renesas/r5f52618bgfp.dtsi:107 */
				#clock-cells = < 0x2 >;             /* in zephyr/dts/rx/renesas/r5f52618bgfp.dtsi:108 */
				status = "okay";                    /* in zephyr/dts/rx/renesas/r5f52618bgfp.dtsi:109 */
				phandle = < 0x10 >;                 /* in zephyr/dts/rx/renesas/rx261-common.dtsi:399 */
			};

			/* node '/clocks/pclkblock@80010/pclkd' defined in zephyr/dts/rx/renesas/r5f52618bgfp.dtsi:112 */
			pclkd: pclkd {
				compatible = "renesas,rx-cgc-pclk"; /* in zephyr/dts/rx/renesas/r5f52618bgfp.dtsi:113 */
				div = < 0x1 >;                      /* in zephyr/dts/rx/renesas/r5f52618bgfp.dtsi:114 */
				#clock-cells = < 0x2 >;             /* in zephyr/dts/rx/renesas/r5f52618bgfp.dtsi:115 */
				status = "okay";                    /* in zephyr/dts/rx/renesas/r5f52618bgfp.dtsi:116 */
			};
		};

		/* node '/clocks/canfdclk' defined in zephyr/dts/rx/renesas/r5f52618bgfp.dtsi:120 */
		canfdclk: canfdclk {
			compatible = "renesas,rx-cgc-pclk"; /* in zephyr/dts/rx/renesas/r5f52618bgfp.dtsi:121 */
			clocks = < &xtal >;                 /* in zephyr/dts/rx/renesas/r5f52618bgfp.dtsi:122 */
			div = < 0x2 >;                      /* in zephyr/dts/rx/renesas/r5f52618bgfp.dtsi:123 */
			#clock-cells = < 0x2 >;             /* in zephyr/dts/rx/renesas/r5f52618bgfp.dtsi:124 */
			status = "disabled";                /* in zephyr/dts/rx/renesas/r5f52618bgfp.dtsi:125 */
		};

		/* node '/clocks/clkout' defined in zephyr/dts/rx/renesas/r5f52618bgfp.dtsi:128 */
		clkout: clkout {
			compatible = "renesas,rx-cgc-pclk"; /* in zephyr/dts/rx/renesas/r5f52618bgfp.dtsi:129 */
			div = < 0x8 >;                      /* in zephyr/dts/rx/renesas/r5f52618bgfp.dtsi:131 */
			#clock-cells = < 0x2 >;             /* in zephyr/dts/rx/renesas/r5f52618bgfp.dtsi:132 */
			status = "disabled";                /* in zephyr/dts/rx/renesas/r5f52618bgfp.dtsi:133 */
			clocks = < &hoco >;                 /* in zephyr/boards/renesas/fpb_rx261/fpb_rx261.dts:58 */
		};

		/* node '/clocks/uclk' defined in zephyr/dts/rx/renesas/r5f52618bgfp.dtsi:136 */
		uclk: uclk {
			compatible = "renesas,rx-cgc-pclk"; /* in zephyr/dts/rx/renesas/r5f52618bgfp.dtsi:137 */
			#clock-cells = < 0x2 >;             /* in zephyr/dts/rx/renesas/r5f52618bgfp.dtsi:139 */
			status = "disabled";                /* in zephyr/dts/rx/renesas/r5f52618bgfp.dtsi:140 */
			clocks = < &hoco >;                 /* in zephyr/boards/renesas/fpb_rx261/fpb_rx261.dts:62 */
		};

		/* node '/clocks/lptclk' defined in zephyr/dts/rx/renesas/r5f52618bgfp.dtsi:143 */
		lptclk: lptclk {
			compatible = "renesas,rx-cgc-pclk"; /* in zephyr/dts/rx/renesas/r5f52618bgfp.dtsi:144 */
			clocks = < &subclk >;               /* in zephyr/dts/rx/renesas/r5f52618bgfp.dtsi:145 */
			#clock-cells = < 0x2 >;             /* in zephyr/dts/rx/renesas/r5f52618bgfp.dtsi:146 */
			status = "disabled";                /* in zephyr/dts/rx/renesas/r5f52618bgfp.dtsi:147 */
		};

		/* node '/clocks/canfdmclk' defined in zephyr/dts/rx/renesas/r5f52618bgfp.dtsi:150 */
		canfdmclk: canfdmclk {
			compatible = "renesas,rx-cgc-pclk"; /* in zephyr/dts/rx/renesas/r5f52618bgfp.dtsi:151 */
			clocks = < &xtal >;                 /* in zephyr/dts/rx/renesas/r5f52618bgfp.dtsi:152 */
			#clock-cells = < 0x2 >;             /* in zephyr/dts/rx/renesas/r5f52618bgfp.dtsi:153 */
			status = "disabled";                /* in zephyr/dts/rx/renesas/r5f52618bgfp.dtsi:154 */
		};

		/* node '/clocks/cacmclk' defined in zephyr/dts/rx/renesas/r5f52618bgfp.dtsi:157 */
		cacmclk: cacmclk {
			compatible = "renesas,rx-cgc-pclk"; /* in zephyr/dts/rx/renesas/r5f52618bgfp.dtsi:158 */
			clocks = < &xtal >;                 /* in zephyr/dts/rx/renesas/r5f52618bgfp.dtsi:159 */
			#clock-cells = < 0x2 >;             /* in zephyr/dts/rx/renesas/r5f52618bgfp.dtsi:160 */
			status = "disabled";                /* in zephyr/dts/rx/renesas/r5f52618bgfp.dtsi:161 */
		};

		/* node '/clocks/cachclk' defined in zephyr/dts/rx/renesas/r5f52618bgfp.dtsi:164 */
		cachclk: cachclk {
			compatible = "renesas,rx-cgc-pclk"; /* in zephyr/dts/rx/renesas/r5f52618bgfp.dtsi:165 */
			clocks = < &hoco >;                 /* in zephyr/dts/rx/renesas/r5f52618bgfp.dtsi:166 */
			#clock-cells = < 0x2 >;             /* in zephyr/dts/rx/renesas/r5f52618bgfp.dtsi:167 */
			status = "disabled";                /* in zephyr/dts/rx/renesas/r5f52618bgfp.dtsi:168 */
		};

		/* node '/clocks/cacsclk' defined in zephyr/dts/rx/renesas/r5f52618bgfp.dtsi:171 */
		cacsclk: cacsclk {
			compatible = "renesas,rx-cgc-pclk"; /* in zephyr/dts/rx/renesas/r5f52618bgfp.dtsi:172 */
			clocks = < &subclk >;               /* in zephyr/dts/rx/renesas/r5f52618bgfp.dtsi:173 */
			#clock-cells = < 0x2 >;             /* in zephyr/dts/rx/renesas/r5f52618bgfp.dtsi:174 */
			status = "disabled";                /* in zephyr/dts/rx/renesas/r5f52618bgfp.dtsi:175 */
		};

		/* node '/clocks/remsclk' defined in zephyr/dts/rx/renesas/r5f52618bgfp.dtsi:178 */
		remsclk: remsclk {
			compatible = "renesas,rx-cgc-pclk"; /* in zephyr/dts/rx/renesas/r5f52618bgfp.dtsi:179 */
			clocks = < &subclk >;               /* in zephyr/dts/rx/renesas/r5f52618bgfp.dtsi:180 */
			#clock-cells = < 0x2 >;             /* in zephyr/dts/rx/renesas/r5f52618bgfp.dtsi:181 */
			status = "disabled";                /* in zephyr/dts/rx/renesas/r5f52618bgfp.dtsi:182 */
		};

		/* node '/clocks/rtcsclk' defined in zephyr/dts/rx/renesas/r5f52618bgfp.dtsi:185 */
		rtcsclk: rtcsclk {
			compatible = "renesas,rx-cgc-pclk"; /* in zephyr/dts/rx/renesas/r5f52618bgfp.dtsi:186 */
			clocks = < &subclk >;               /* in zephyr/dts/rx/renesas/r5f52618bgfp.dtsi:187 */
			#clock-cells = < 0x2 >;             /* in zephyr/dts/rx/renesas/r5f52618bgfp.dtsi:188 */
			status = "disabled";                /* in zephyr/dts/rx/renesas/r5f52618bgfp.dtsi:189 */
		};

		/* node '/clocks/caclclk' defined in zephyr/dts/rx/renesas/r5f52618bgfp.dtsi:192 */
		caclclk: caclclk {
			compatible = "renesas,rx-cgc-pclk"; /* in zephyr/dts/rx/renesas/r5f52618bgfp.dtsi:193 */
			clocks = < &loco >;                 /* in zephyr/dts/rx/renesas/r5f52618bgfp.dtsi:194 */
			#clock-cells = < 0x2 >;             /* in zephyr/dts/rx/renesas/r5f52618bgfp.dtsi:195 */
			status = "disabled";                /* in zephyr/dts/rx/renesas/r5f52618bgfp.dtsi:196 */
		};

		/* node '/clocks/iwdtclk' defined in zephyr/dts/rx/renesas/r5f52618bgfp.dtsi:199 */
		iwdtclk: iwdtclk {
			compatible = "renesas,rx-cgc-pclk"; /* in zephyr/dts/rx/renesas/r5f52618bgfp.dtsi:200 */
			clocks = < &iwdtlsclk >;            /* in zephyr/dts/rx/renesas/r5f52618bgfp.dtsi:201 */
			#clock-cells = < 0x2 >;             /* in zephyr/dts/rx/renesas/r5f52618bgfp.dtsi:202 */
			status = "disabled";                /* in zephyr/dts/rx/renesas/r5f52618bgfp.dtsi:203 */
		};
	};

	/* node '/chosen' defined in zephyr/boards/renesas/fpb_rx261/fpb_rx261.dts:17 */
	chosen {
		zephyr,sram = &sram0;       /* in zephyr/boards/renesas/fpb_rx261/fpb_rx261.dts:18 */
		zephyr,flash = &code_flash; /* in zephyr/boards/renesas/fpb_rx261/fpb_rx261.dts:19 */
		zephyr,console = &uart5;    /* in zephyr/boards/renesas/fpb_rx261/fpb_rx261.dts:20 */
		zephyr,shell-uart = &uart5; /* in zephyr/boards/renesas/fpb_rx261/fpb_rx261.dts:21 */
	};

	/* node '/leds' defined in zephyr/boards/renesas/fpb_rx261/fpb_rx261.dts:24 */
	leds {
		compatible = "gpio-leds"; /* in zephyr/boards/renesas/fpb_rx261/fpb_rx261.dts:25 */

		/* node '/leds/led1' defined in zephyr/boards/renesas/fpb_rx261/fpb_rx261.dts:27 */
		led1: led1 {
			gpios = < &ioportj 0x1 0x1 >; /* in zephyr/boards/renesas/fpb_rx261/fpb_rx261.dts:28 */
			label = "LED1";               /* in zephyr/boards/renesas/fpb_rx261/fpb_rx261.dts:29 */
		};

		/* node '/leds/led2' defined in zephyr/boards/renesas/fpb_rx261/fpb_rx261.dts:32 */
		led2: led2 {
			gpios = < &ioportc 0x5 0x1 >; /* in zephyr/boards/renesas/fpb_rx261/fpb_rx261.dts:33 */
			label = "LED2";               /* in zephyr/boards/renesas/fpb_rx261/fpb_rx261.dts:34 */
		};
	};

	/* node '/aliases' defined in zephyr/boards/renesas/fpb_rx261/fpb_rx261.dts:38 */
	aliases {
		led0 = &led1; /* in zephyr/boards/renesas/fpb_rx261/fpb_rx261.dts:39 */
		led1 = &led2; /* in zephyr/boards/renesas/fpb_rx261/fpb_rx261.dts:40 */
	};
};
